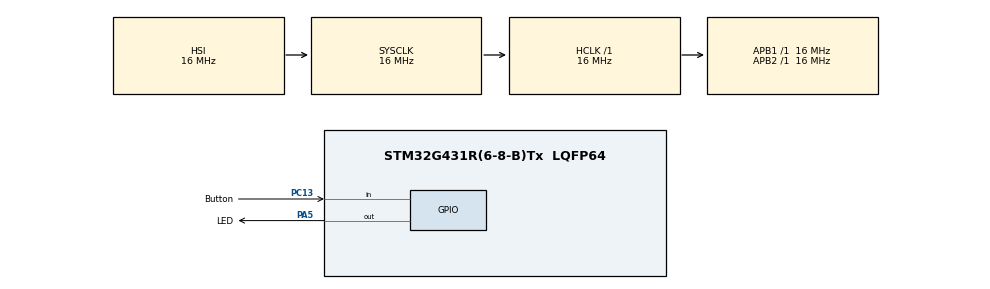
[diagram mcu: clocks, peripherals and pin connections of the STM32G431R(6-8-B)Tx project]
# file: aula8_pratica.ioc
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Mcu.Family=STM32G4
Mcu.Name=STM32G431R(6-8-B)Tx
Mcu.Package=LQFP64
NVIC.PriorityGroup=NVIC_PRIORITYGROUP_4
PA13.Mode=Serial_Wire
PA13.Signal=SYS_JTMS-SWDIO
PA14.Mode=Serial_Wire
PA14.Signal=SYS_JTCK-SWCLK
PA5.GPIO_Label=LED
PA5.Signal=GPIO_Output
PC13.GPIO_Label=Button
PC13.Signal=GPIO_Input
PF0-OSC_IN.Mode=HSE-External-Oscillator
PF0-OSC_IN.Signal=RCC_OSC_IN
PF1-OSC_OUT.Mode=HSE-External-Oscillator
PF1-OSC_OUT.Signal=RCC_OSC_OUT
ProjectManager.HeapSize=0x200
ProjectManager.StackSize=0x400
ProjectManager.TargetToolchain=STM32CubeIDE
RCC.AHBFreq_Value=16000000
RCC.APB1Freq_Value=16000000
RCC.APB1TimFreq_Value=16000000
RCC.APB2Freq_Value=16000000
RCC.APB2TimFreq_Value=16000000
RCC.CortexFreq_Value=16000000
RCC.EXTERNAL_CLOCK_VALUE=12288000
RCC.HCLKFreq_Value=16000000
RCC.HSE_VALUE=8000000
RCC.HSI48_VALUE=48000000
RCC.HSI_VALUE=16000000
RCC.LSE_VALUE=32768
RCC.PLLSourceVirtual=RCC_PLLSOURCE_HSE
RCC.SYSCLKFreq_VALUE=16000000
RCC.USBFreq_Value=32000000
RCC.VCOOutputFreq_Value=64000000
VP_SYS_VS_DBSignals.Mode=DisableDeadBatterySignals
board=custom

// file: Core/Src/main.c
/* USER CODE BEGIN Header */
/**
  ******************************************************************************
  * @file           : main.c
  * @brief          : Main program body
  ******************************************************************************
  * @attention
  *
  * Copyright (c) 2025 STMicroelectronics.
  * All rights reserved.
  *
  * This software is licensed under terms that can be found in the LICENSE file
  * in the root directory of this software component.
  * If no LICENSE file comes with this software, it is provided AS-IS.
  *
  ******************************************************************************
  */
/* USER CODE END Header */
#include "main.h"

/* USER CODE BEGIN Includes */
#include "pt.h"
#include "pt-sem.h"

/* USER CODE END Includes */

void SystemClock_Config(void);
static void MX_GPIO_Init(void);

/* USER CODE BEGIN 0 */

#define SLEEP(pt, timeout) \
	do{ \
		pt->start_time = HAL_GetTick(); \
		PT_WAIT_UNTIL(pt, (HAL_GetTick() - pt->start_time) >= timeout); \
	}while(0)

struct pt pt_led;
struct pt pt_button;
struct pt_sem sem_button;

int protothread_led(struct pt *pt)
{
	PT_BEGIN(pt);

	while(1)
	{
		SLEEP(pt, 200);
		HAL_GPIO_TogglePin(GPIOA, GPIO_PIN_5);
	}

	PT_END(pt);
}

//void HAL_GPIO_EXTI_Callback(uint16_t GPIO_Pin)
//{
//	HAL_NVIC_DisableIRQ(EXTI15_10_IRQn);
//	PT_SEM_WAIT(pt_button, sem_button);
//}

int protothread_button(struct pt *pt)
{
	return 0;
}

/* USER CODE END 0 */

int main(void)
{

  /* MCU Configuration--------------------------------------------------------*/

  /* Reset of all peripherals, Initializes the Flash interface and the Systick. */
  HAL_Init();

  /* USER CODE BEGIN Init */
  PT_INIT(&pt_led);
  PT_INIT(&pt_button);
//  PT_SEM_INIT(sem_button, 1);
  /* USER CODE END Init */

  /* Configure the system clock */
  SystemClock_Config();

  /* Initialize all configured peripherals */
  MX_GPIO_Init();

  /* Infinite loop */
  while (1)
  {

    /* USER CODE BEGIN 3 */
	  protothread_led(&pt_led);
  }
  /* USER CODE END 3 */
}

void SystemClock_Config(void)
{
  RCC_OscInitTypeDef RCC_OscInitStruct = {0};
  RCC_ClkInitTypeDef RCC_ClkInitStruct = {0};

  /** Configure the main internal regulator output voltage
  */
  HAL_PWREx_ControlVoltageScaling(PWR_REGULATOR_VOLTAGE_SCALE1);

  /** Initializes the RCC Oscillators according to the specified parameters
  * in the RCC_OscInitTypeDef structure.
  */
  RCC_OscInitStruct.OscillatorType = RCC_OSCILLATORTYPE_HSI;
  RCC_OscInitStruct.HSIState = RCC_HSI_ON;
  RCC_OscInitStruct.HSICalibrationValue = RCC_HSICALIBRATION_DEFAULT;
  RCC_OscInitStruct.PLL.PLLState = RCC_PLL_NONE;
  if (HAL_RCC_OscConfig(&RCC_OscInitStruct) != HAL_OK)
  {
    Error_Handler();
  }

  /** Initializes the CPU, AHB and APB buses clocks
  */
  RCC_ClkInitStruct.ClockType = RCC_CLOCKTYPE_HCLK|RCC_CLOCKTYPE_SYSCLK
                              |RCC_CLOCKTYPE_PCLK1|RCC_CLOCKTYPE_PCLK2;
  RCC_ClkInitStruct.SYSCLKSource = RCC_SYSCLKSOURCE_HSI;
  RCC_ClkInitStruct.AHBCLKDivider = RCC_SYSCLK_DIV1;
  RCC_ClkInitStruct.APB1CLKDivider = RCC_HCLK_DIV1;
  RCC_ClkInitStruct.APB2CLKDivider = RCC_HCLK_DIV1;

  if (HAL_RCC_ClockConfig(&RCC_ClkInitStruct, FLASH_LATENCY_0) != HAL_OK)
  {
    Error_Handler();
  }
}

static void MX_GPIO_Init(void)
{
  GPIO_InitTypeDef GPIO_InitStruct = {0};

  /* GPIO Ports Clock Enable */
  __HAL_RCC_GPIOC_CLK_ENABLE();
  __HAL_RCC_GPIOF_CLK_ENABLE();
  __HAL_RCC_GPIOA_CLK_ENABLE();

  /*Configure GPIO pin Output Level */
  HAL_GPIO_WritePin(LED_GPIO_Port, LED_Pin, GPIO_PIN_RESET);

  /*Configure GPIO pin : Button_Pin */
  GPIO_InitStruct.Pin = Button_Pin;
  GPIO_InitStruct.Mode = GPIO_MODE_INPUT;
  GPIO_InitStruct.Pull = GPIO_NOPULL;
  HAL_GPIO_Init(Button_GPIO_Port, &GPIO_InitStruct);

  /*Configure GPIO pin : LED_Pin */
  GPIO_InitStruct.Pin = LED_Pin;
  GPIO_InitStruct.Mode = GPIO_MODE_OUTPUT_PP;
  GPIO_InitStruct.Pull = GPIO_NOPULL;
  GPIO_InitStruct.Speed = GPIO_SPEED_FREQ_LOW;
  HAL_GPIO_Init(LED_GPIO_Port, &GPIO_InitStruct);

}

void Error_Handler(void)
{
  __disable_irq();
  while (1)
  {
  }
}
